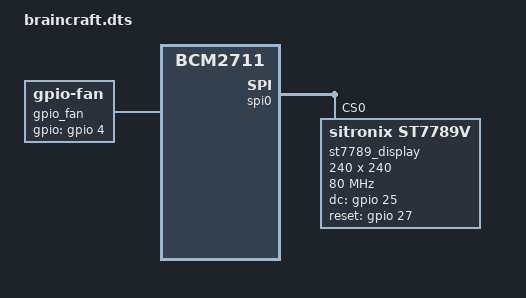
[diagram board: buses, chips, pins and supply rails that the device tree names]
/dts-v1/;
/plugin/;

/ {
    compatible = "brcm,bcm2711";

    /* ST7789 SPI display on BrainCraft HAT */
    fragment@0 {
        target = <&spi0>;
        __overlay__ {
            #address-cells = <1>;
            #size-cells = <0>;
            status = "okay";

            st7789_display: display@0 {
                compatible = "sitronix,st7789v";
                reg = <0>;
                spi-max-frequency = <80000000>;
                dc-gpios = <&gpio 25 0>;
                reset-gpios = <&gpio 27 0>;
                rotation = <90>;
                width = <240>;
                height = <240>;
            };
        };
    };

    /* PDM microphones on BrainCraft HAT */
    fragment@1 {
        target-path = "/";
        __overlay__ {
            pdm_sound: sound {
                compatible = "simple-audio-card";
                simple-audio-card,name = "BrainCraft PDM";

                simple-audio-card,cpu {
                    sound-dai = <&i2s>;
                };
            };
        };
    };

    /* Thermal fan control */
    fragment@2 {
        target-path = "/";
        __overlay__ {
            gpio_fan: gpio-fan {
                compatible = "gpio-fan";
                gpios = <&gpio 4 0>;
                gpio-fan,speed-map = <0 0>, <6000 1>;
                cooling-min-state = <0>;
                cooling-max-state = <1>;
                #cooling-cells = <2>;
            };
        };
    };
};
